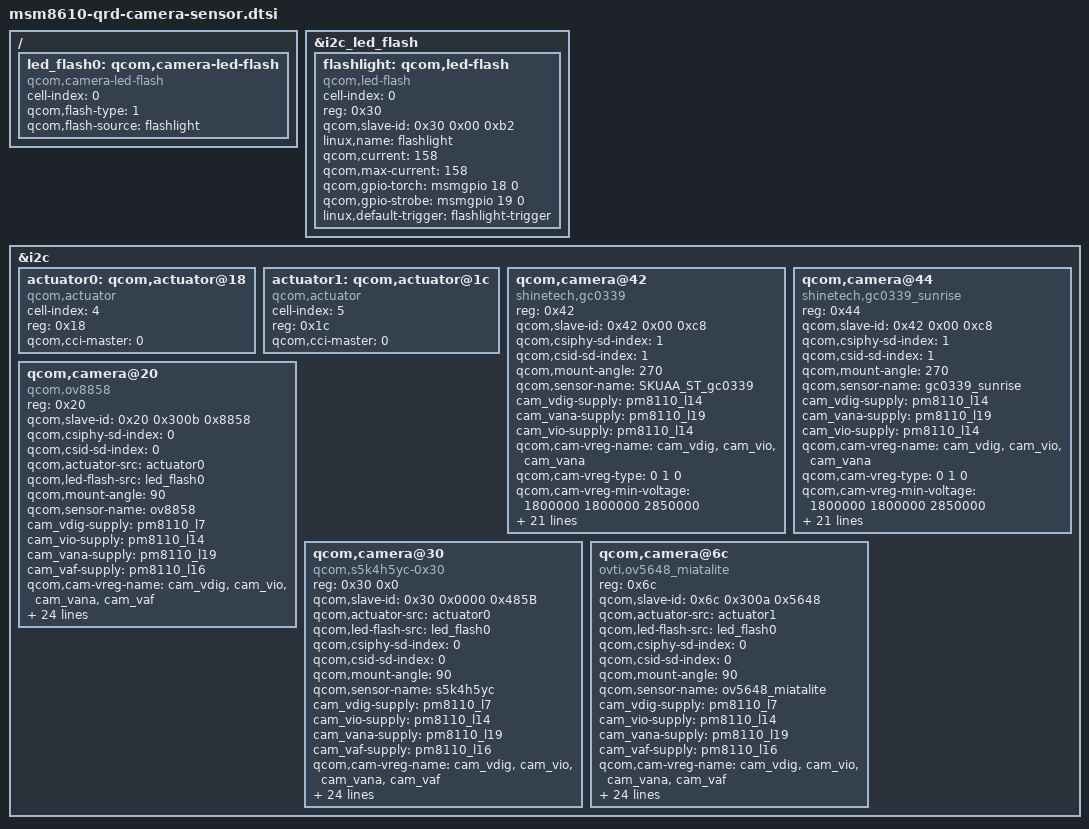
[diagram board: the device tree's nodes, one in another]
/*
 * Copyright (c) 2012-2013, The Linux Foundation. All rights reserved.
 *
 * This program is free software; you can redistribute it and/or modify
 * it under the terms of the GNU General Public License version 2 and
 * only version 2 as published by the Free Software Foundation.
 *
 * This program is distributed in the hope that it will be useful,
 * but WITHOUT ANY WARRANTY; without even the implied warranty of
 * MERCHANTABILITY or FITNESS FOR A PARTICULAR PURPOSE.  See the
 * GNU General Public License for more details.
 */
//Begin-[Bug 540542]BSP porting LED FLASH by weicai.long@tcl.com, 2013/10/24.
&i2c_led_flash {
    flashlight: qcom,led-flash {
        cell-index = <0>;
        reg = <0x30>;
        qcom,slave-id = <0x30 0x00 0xb2>;
        compatible = "qcom,led-flash";
        linux,name = "flashlight";
        qcom,current = <158>;
        qcom,max-current = <158>;
        //qcom,gpio-flash = <&msmgpio 18 0>;
        qcom,gpio-torch = <&msmgpio 18 0>;
        qcom,gpio-strobe = <&msmgpio 19 0>;
        linux,default-trigger = "flashlight-trigger";
    };
};

/ {
    led_flash0: qcom,camera-led-flash {
        cell-index = <0>;
        compatible = "qcom,camera-led-flash";
        qcom,flash-type = <1>;
        qcom,flash-source = <&flashlight>;
    };
};
//End-[Bug 540542]BSP porting LED FLASH by weicai.long@tcl.com, 2013/10/24.
&i2c {
    actuator0: qcom,actuator@18 {
        cell-index = <4>;
        reg = <0x18>;
        compatible = "qcom,actuator";
        qcom,cci-master = <0>;
    };
    actuator1: qcom,actuator@1c {
		cell-index = <5>;
		reg = <0x1c>;
		compatible = "qcom,actuator";
		qcom,cci-master = <0>;
	};

	qcom,camera@42 {
		compatible = "shinetech,gc0339";
		reg = <0x42>;
		qcom,slave-id = <0x42 0x00 0xc8>;
		qcom,csiphy-sd-index = <1>;
		qcom,csid-sd-index = <1>;
		qcom,mount-angle = <270>;
		qcom,sensor-name = "SKUAA_ST_gc0339";
		cam_vdig-supply = <&pm8110_l14>;
		cam_vana-supply = <&pm8110_l19>;
		cam_vio-supply = <&pm8110_l14>;
		qcom,cam-vreg-name = "cam_vdig", "cam_vio", "cam_vana";
		qcom,cam-vreg-type = <0 1 0>;
		qcom,cam-vreg-min-voltage = <1800000 1800000 2850000>;
		qcom,cam-vreg-max-voltage = <1800000 1800000 2850000>;
		qcom,cam-vreg-op-mode = <200000 0 80000>;
		qcom,gpio-no-mux = <0>;
		gpios = <&msmgpio 14 0>,
				<&msmgpio 15 0>,
				<&msmgpio 85 0>,
                <&msmgpio 43 0>;
		qcom,gpio-reset = <1>;
		qcom,gpio-standby = <2>;
		qcom,gpio-vana = <3>;
		qcom,gpio-req-tbl-num = <0 1 2 3>;
		qcom,gpio-req-tbl-flags = <1 0 0 0>;
		qcom,gpio-req-tbl-label = "CAMIF_MCLK",
				"CAM_RESET",
				"CAM_STANDBY",
                "CAM_VANA_LDO_EN";
		qcom,gpio-set-tbl-num = <1 1>;
		qcom,gpio-set-tbl-flags = <0 2>;
		qcom,gpio-set-tbl-delay = <1000 4000>;
		qcom,csi-lane-assign = <0xe4>;
		qcom,csi-lane-mask = <0x3>;
		qcom,sensor-position = <1>;
		qcom,sensor-mode = <1>;
		qcom,cci-master = <0>;
		status = "ok";
	};
//qiangbo.ni add sub camera second module sunrise 2014-07-04 begin
	qcom,camera@44 {
		compatible = "shinetech,gc0339_sunrise";
		reg = <0x44>;
		qcom,slave-id = <0x42 0x00 0xc8>;
		qcom,csiphy-sd-index = <1>;
		qcom,csid-sd-index = <1>;
		qcom,mount-angle = <270>;
		qcom,sensor-name = "gc0339_sunrise";
		cam_vdig-supply = <&pm8110_l14>;
		cam_vana-supply = <&pm8110_l19>;
		cam_vio-supply = <&pm8110_l14>;
		qcom,cam-vreg-name = "cam_vdig", "cam_vio", "cam_vana";
		qcom,cam-vreg-type = <0 1 0>;
		qcom,cam-vreg-min-voltage = <1800000 1800000 2850000>;
		qcom,cam-vreg-max-voltage = <1800000 1800000 2850000>;
		qcom,cam-vreg-op-mode = <200000 0 80000>;
		qcom,gpio-no-mux = <0>;
		gpios = <&msmgpio 14 0>,
				<&msmgpio 15 0>,
				<&msmgpio 85 0>,
                <&msmgpio 43 0>;
		qcom,gpio-reset = <1>;
		qcom,gpio-standby = <2>;
		qcom,gpio-vana = <3>;
		qcom,gpio-req-tbl-num = <0 1 2 3>;
		qcom,gpio-req-tbl-flags = <1 0 0 0>;
		qcom,gpio-req-tbl-label = "CAMIF_MCLK",
				"CAM_RESET",
				"CAM_STANDBY",
                "CAM_VANA_LDO_EN";
		qcom,gpio-set-tbl-num = <1 1>;
		qcom,gpio-set-tbl-flags = <0 2>;
		qcom,gpio-set-tbl-delay = <1000 4000>;
		qcom,csi-lane-assign = <0xe4>;
		qcom,csi-lane-mask = <0x3>;
		qcom,sensor-position = <1>;
		qcom,sensor-mode = <1>;
		qcom,cci-master = <0>;
		status = "ok";
	};
//qiangbo.ni add sub camera second module sunrise 2014-07-04 end
//Begin add by weicai.long@tcl.com for camera driver, 2013/11/07.
/*    qcom,camera@6c {
        compatible = "qcom,s5k4h5yc";
        reg = <0x6c 0x0>;
        qcom,slave-id = <0x20 0x0000 0x485B>;
        qcom,actuator-src = <&actuator0>;
        qcom,led-flash-src = <&led_flash0>;
        qcom,csiphy-sd-index = <0>;
        qcom,csid-sd-index = <0>;
        qcom,mount-angle = <90>;
        qcom,sensor-name = "s5k4h5yc";
        cam_vdig-supply = <&pm8110_l7>;
        cam_vio-supply = <&pm8110_l14>;
        cam_vana-supply = <&pm8110_l19>;
        cam_vaf-supply = <&pm8110_l16>;
        qcom,cam-vreg-name = "cam_vdig","cam_vio", "cam_vana", "cam_vaf";
        qcom,cam-vreg-type = <0 0 0 0>;
        qcom,cam-vreg-min-voltage = <1200000 1800000 2850000 3000000>;
        qcom,cam-vreg-max-voltage = <1200000 1800000 2850000 3000000>;
        qcom,cam-vreg-op-mode = <200000 8000 80000 100000>;
        qcom,gpio-no-mux = <0>;
        gpios = <&msmgpio 13 0>,
                <&msmgpio 21 0>,
                <&msmgpio 20 0>,
                <&msmgpio 43 0>,
                <&msmgpio 78 0>;
        qcom,gpio-reset = <1>;
        qcom,gpio-standby = <2>;
        qcom,gpio-vana = <3>;
        qcom,gpio-af-pwdm = <4>;
        qcom,gpio-req-tbl-num = <0 1 2 3 4>;
        qcom,gpio-req-tbl-flags = <1 0 0 0 0>;
        qcom,gpio-req-tbl-label = "CAMIF_MCLK",
                "CAM_RESET",
                "CAM_STANDBY",
                "CAM_VANA",
                "CAM_AF_PWDM";
        qcom,gpio-set-tbl-flags = <0 2>;
        qcom,gpio-set-tbl-delay = <1000 4000>;
        qcom,csi-lane-assign = <0xe4>;
        qcom,csi-lane-mask = <0x3>;
        qcom,sensor-position = <0>;
        qcom,sensor-mode = <1>;
        qcom,cci-master = <0>;
    };
*/
	qcom,camera@20 {
		compatible = "qcom,ov8858";
		reg = <0x20>;
		qcom,slave-id = <0x20 0x300b 0x8858>;
		qcom,csiphy-sd-index = <0>;
		qcom,csid-sd-index = <0>;
		qcom,actuator-src = <&actuator0>;
		qcom,led-flash-src = <&led_flash0>;
		qcom,mount-angle = <90>;
		qcom,sensor-name = "ov8858";
		cam_vdig-supply = <&pm8110_l7>;
		cam_vio-supply = <&pm8110_l14>;
        cam_vana-supply = <&pm8110_l19>;
		cam_vaf-supply = <&pm8110_l16>;
		qcom,cam-vreg-name = "cam_vdig", "cam_vio", "cam_vana", "cam_vaf";
		qcom,cam-vreg-type = <0 0 0 0>;
		qcom,cam-vreg-min-voltage = <1200000 1800000 2850000 3000000>;
		qcom,cam-vreg-max-voltage = <1200000 1800000 2850000 3000000>;
		qcom,cam-vreg-op-mode = <200000 8000 80000 100000>;
		qcom,gpio-no-mux = <0>;
		gpios = <&msmgpio 13 0>,
			<&msmgpio 21 0>,//reset
			<&msmgpio 20 0>,//stanby
			<&msmgpio 43 0>, //avdd_en
			<&msmgpio 78 0>; //vcm_pwdn
		qcom,gpio-reset = <1>;
		qcom,gpio-standby = <2>;
        qcom,gpio-vana = <3>;
        qcom,gpio-af-pwdm = <4>;
		qcom,gpio-req-tbl-num = <0 1 2 3 4>;
		qcom,gpio-req-tbl-flags = <1 0 0 0 0>;
		qcom,gpio-req-tbl-label = "CAMIF_MCLK",
			"CAM_RESET",
			"CAM_STANDBY",
			"CAM_AVDDEN",
			"CAM_VCMPWDN";
		qcom,csi-lane-assign = <0xe4>;
		qcom,csi-lane-mask = <0x3>;
		qcom,sensor-position = <0>;
		qcom,sensor-mode = <1>;
		qcom,cci-master = <0>;
    };
    qcom,camera@30 {
        compatible = "qcom,s5k4h5yc-0x30";
        reg = <0x30 0x0>;
        qcom,slave-id = <0x30 0x0000 0x485B>;
        qcom,actuator-src = <&actuator0>;
        qcom,led-flash-src = <&led_flash0>;
        qcom,csiphy-sd-index = <0>;
        qcom,csid-sd-index = <0>;
        qcom,mount-angle = <90>;
        qcom,sensor-name = "s5k4h5yc";
        cam_vdig-supply = <&pm8110_l7>;
        cam_vio-supply = <&pm8110_l14>;
        cam_vana-supply = <&pm8110_l19>;
        cam_vaf-supply = <&pm8110_l16>;
        qcom,cam-vreg-name = "cam_vdig","cam_vio", "cam_vana", "cam_vaf";
        qcom,cam-vreg-type = <0 0 0 0>;
        qcom,cam-vreg-min-voltage = <1200000 1800000 2850000 3000000>;
        qcom,cam-vreg-max-voltage = <1200000 1800000 2850000 3000000>;
        qcom,cam-vreg-op-mode = <200000 8000 80000 100000>;
        qcom,gpio-no-mux = <0>;
        gpios = <&msmgpio 13 0>,
                <&msmgpio 21 0>,
                <&msmgpio 20 0>,
                <&msmgpio 43 0>,
                <&msmgpio 78 0>;
        qcom,gpio-reset = <1>;
        qcom,gpio-standby = <2>;
        qcom,gpio-vana = <3>;
        qcom,gpio-af-pwdm = <4>;
        qcom,gpio-req-tbl-num = <0 1 2 3 4>;
        qcom,gpio-req-tbl-flags = <1 0 0 0 0>;
        qcom,gpio-req-tbl-label = "CAMIF_MCLK",
                "CAM_RESET",
                "CAM_STANDBY",
                "CAM_VANA",
                "CAM_AF_PWDM";
        qcom,csi-lane-assign = <0xe4>;
        qcom,csi-lane-mask = <0x3>;
        qcom,sensor-position = <0>;
        qcom,sensor-mode = <1>;
        qcom,cci-master = <0>;
    };
    qcom,camera@6c {
        compatible = "ovti,ov5648_miatalite";
        reg = <0x6c>;
        qcom,slave-id = <0x6c 0x300a 0x5648>;
        qcom,actuator-src = <&actuator1>;
        qcom,led-flash-src = <&led_flash0>;
        qcom,csiphy-sd-index = <0>;
        qcom,csid-sd-index = <0>;
        qcom,mount-angle = <90>;
        qcom,sensor-name = "ov5648_miatalite";
        cam_vdig-supply = <&pm8110_l7>;
        cam_vio-supply = <&pm8110_l14>;
        cam_vana-supply = <&pm8110_l19>;
        cam_vaf-supply = <&pm8110_l16>;
        qcom,cam-vreg-name = "cam_vdig","cam_vio", "cam_vana", "cam_vaf";
        qcom,cam-vreg-type = <0 0 0 0>;
        qcom,cam-vreg-min-voltage = <1500000 1800000 2850000 3000000>;
        qcom,cam-vreg-max-voltage = <1500000 1800000 2850000 3000000>;
        qcom,cam-vreg-op-mode = <200000 8000 80000 100000>;
        qcom,gpio-no-mux = <0>;
        gpios = <&msmgpio 13 0>,
                <&msmgpio 21 0>,
                <&msmgpio 20 0>,
                <&msmgpio 43 0>,
                <&msmgpio 78 0>;
        qcom,gpio-reset = <1>;
        qcom,gpio-standby = <2>;
        qcom,gpio-vana = <3>;
        qcom,gpio-af-pwdm = <4>;
        qcom,gpio-req-tbl-num = <0 1 2 3 4>;
        qcom,gpio-req-tbl-flags = <1 0 0 0 0>;
        qcom,gpio-req-tbl-label = "CAMIF_MCLK",
                "CAM_RESET",
                "CAM_STANDBY",
                "CAM_VANA",
                "CAM_AF_PWDM";
        qcom,csi-lane-assign = <0xe4>;
        qcom,csi-lane-mask = <0x3>;
        qcom,sensor-position = <0>;
        qcom,sensor-mode = <1>;
        qcom,cci-master = <0>;
    };
//End add by weicai.long@tcl.com for camera driver, 2013/11/07.
};

